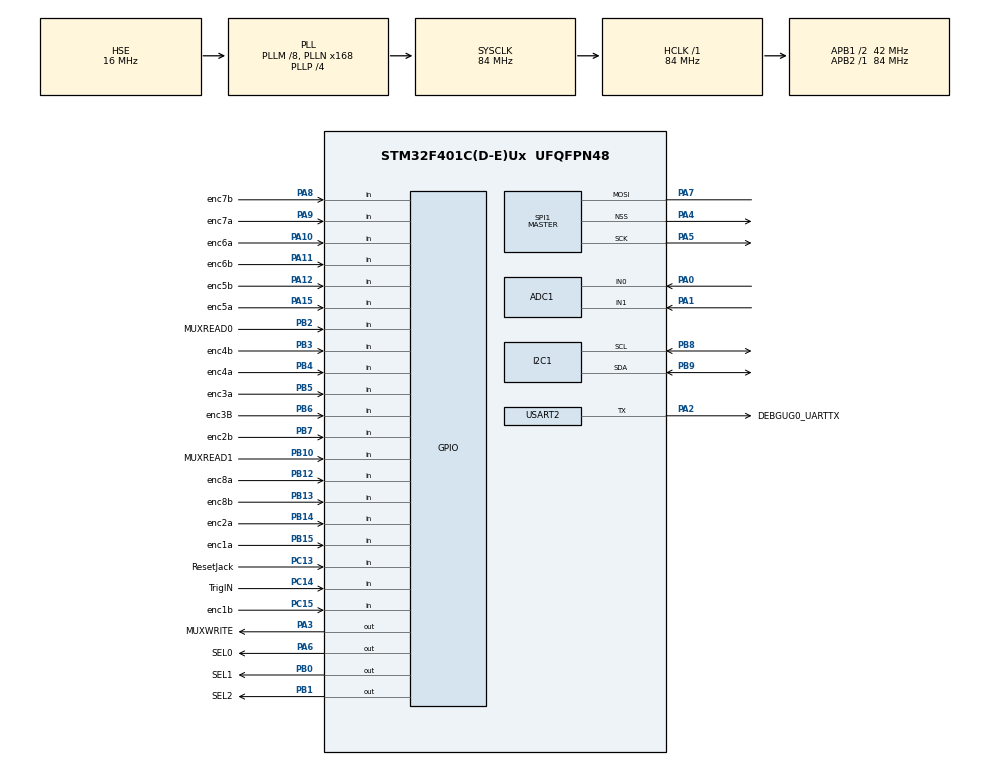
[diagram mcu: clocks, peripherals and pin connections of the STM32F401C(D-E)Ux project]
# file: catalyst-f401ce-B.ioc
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ADC1.Channel-0\#ChannelRegularConversion=ADC_CHANNEL_0
ADC1.Channel-1\#ChannelRegularConversion=ADC_CHANNEL_1
ADC1.ClockPrescaler=ADC_CLOCK_SYNC_PCLK_DIV4
ADC1.ContinuousConvMode=ENABLE
ADC1.DMAContinuousRequests=ENABLE
ADC1.EOCSelection=ADC_EOC_SEQ_CONV
ADC1.NbrOfConversion=2
ADC1.NbrOfConversionFlag=1
ADC1.Rank-0\#ChannelRegularConversion=1
ADC1.Rank-1\#ChannelRegularConversion=2
ADC1.SamplingTime-0\#ChannelRegularConversion=ADC_SAMPLETIME_84CYCLES
ADC1.SamplingTime-1\#ChannelRegularConversion=ADC_SAMPLETIME_84CYCLES
ADC1.ScanConvMode=ENABLE
ADC1.master=1
Dma.ADC1.0.Direction=DMA_PERIPH_TO_MEMORY
Dma.ADC1.0.FIFOMode=DMA_FIFOMODE_DISABLE
Dma.ADC1.0.Instance=DMA2_Stream0
Dma.ADC1.0.MemDataAlignment=DMA_MDATAALIGN_HALFWORD
Dma.ADC1.0.MemInc=DMA_MINC_ENABLE
Dma.ADC1.0.Mode=DMA_NORMAL
Dma.ADC1.0.PeriphDataAlignment=DMA_PDATAALIGN_HALFWORD
Dma.ADC1.0.PeriphInc=DMA_PINC_DISABLE
Dma.ADC1.0.Priority=DMA_PRIORITY_LOW
Dma.Request0=ADC1
I2C1.I2C_Mode=I2C_Fast
Mcu.Family=STM32F4
Mcu.Name=STM32F401C(D-E)Ux
Mcu.Package=UFQFPN48
NVIC.DMA2_Stream0_IRQn=true\:0\:0\:false\:false\:true\:false\:true\:true
NVIC.PriorityGroup=NVIC_PRIORITYGROUP_4
PA0-WKUP.Signal=ADCx_IN0
PA1.Signal=ADCx_IN1
PA10.GPIO_Label=enc6a
PA10.Signal=GPIO_Input
PA11.GPIO_Label=enc6b
PA11.Signal=GPIO_Input
PA12.GPIO_Label=enc5b
PA12.Signal=GPIO_Input
PA13.Mode=Serial_Wire
PA13.Signal=SYS_JTMS-SWDIO
PA14.Mode=Serial_Wire
PA14.Signal=SYS_JTCK-SWCLK
PA15.GPIO_Label=enc5a
PA15.Signal=GPIO_Input
PA2.GPIO_Label=DEBGUG0_UARTTX
PA2.Mode=Half_duplex(single_wire_mode)
PA2.Signal=USART2_TX
PA3.GPIO_Label=MUXWRITE
PA3.Signal=GPIO_Output
PA4.Mode=NSS_Signal_Hard_Output
PA4.Signal=SPI1_NSS
PA5.Mode=Simplex_Bidirectional_Master
PA5.Signal=SPI1_SCK
PA6.GPIO_Label=SEL0
PA6.Signal=GPIO_Output
PA7.Mode=Simplex_Bidirectional_Master
PA7.Signal=SPI1_MOSI
PA8.GPIO_Label=enc7b
PA8.Signal=GPIO_Input
PA9.GPIO_Label=enc7a
PA9.Signal=GPIO_Input
PB0.GPIO_Label=SEL1
PB0.Signal=GPIO_Output
PB1.GPIO_Label=SEL2
PB1.Signal=GPIO_Output
PB10.GPIO_Label=MUXREAD1
PB10.Signal=GPIO_Input
PB12.GPIO_Label=enc8a
PB12.Signal=GPIO_Input
PB13.GPIO_Label=enc8b
PB13.Signal=GPIO_Input
PB14.GPIO_Label=enc2a
PB14.Signal=GPIO_Input
PB15.GPIO_Label=enc1a
PB15.Signal=GPIO_Input
PB2.GPIO_Label=MUXREAD0
PB2.Signal=GPIO_Input
PB3.GPIO_Label=enc4b
PB3.Signal=GPIO_Input
PB4.GPIO_Label=enc4a
PB4.Signal=GPIO_Input
PB5.GPIO_Label=enc3a
PB5.Signal=GPIO_Input
PB6.GPIO_Label=enc3B
PB6.Signal=GPIO_Input
PB7.GPIO_Label=enc2b
PB7.Signal=GPIO_Input
PB8.Mode=I2C
PB8.Signal=I2C1_SCL
PB9.Mode=I2C
PB9.Signal=I2C1_SDA
PC13-ANTI_TAMP.GPIO_Label=ResetJack
PC13-ANTI_TAMP.Signal=GPIO_Input
PC14-OSC32_IN.GPIO_Label=TrigIN
PC14-OSC32_IN.Signal=GPIO_Input
PC15-OSC32_OUT.GPIO_Label=enc1b
PC15-OSC32_OUT.Signal=GPIO_Input
PH0\ -\ OSC_IN.Mode=HSE-External-Oscillator
PH0\ -\ OSC_IN.Signal=RCC_OSC_IN
PH1\ -\ OSC_OUT.Mode=HSE-External-Oscillator
PH1\ -\ OSC_OUT.Signal=RCC_OSC_OUT
ProjectManager.HeapSize=0x200
ProjectManager.StackSize=0x400
ProjectManager.TargetToolchain=Makefile
RCC.48MHZClocksFreq_Value=48000000
RCC.AHBFreq_Value=84000000
RCC.APB1CLKDivider=RCC_HCLK_DIV2
RCC.APB1Freq_Value=42000000
RCC.APB1TimFreq_Value=84000000
RCC.APB2Freq_Value=84000000
RCC.APB2TimFreq_Value=84000000
RCC.CortexFreq_Value=84000000
RCC.HCLKFreq_Value=84000000
RCC.HSE_VALUE=16000000
RCC.HSI_VALUE=16000000
RCC.LSE_VALUE=32768
RCC.PLLM=8
RCC.PLLN=168
RCC.PLLP=RCC_PLLP_DIV4
RCC.PLLQ=7
RCC.PLLSourceVirtual=RCC_PLLSOURCE_HSE
RCC.SYSCLKFreq_VALUE=84000000
RCC.SYSCLKSource=RCC_SYSCLKSOURCE_PLLCLK
RCC.VCOOutputFreq_Value=336000000
SH.ADCx_IN0.0=ADC1_IN0,IN0
SH.ADCx_IN1.0=ADC1_IN1,IN1
SPI1.Direction=SPI_DIRECTION_1LINE
SPI1.Mode=SPI_MODE_MASTER
SPI1.VirtualNSS=VM_NSSHARD
SPI1.VirtualType=VM_MASTER
USART2.Mode=MODE_TX
USART2.VirtualMode=VM_ASYNC
board=custom

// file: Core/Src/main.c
#include "main.h"
#include "stm32f4xx_hal_i2c.h"

ADC_HandleTypeDef hadc1;
DMA_HandleTypeDef hdma_adc1;

I2C_HandleTypeDef hi2c1;

SPI_HandleTypeDef hspi1;

void SystemClock_Config(void);
static void MX_GPIO_Init(void);
static void MX_DMA_Init(void);
static void MX_ADC1_Init(void);
static void MX_SPI1_Init(void);
static void MX_I2C1_Init(void);

//
// LEDs
//

HAL_StatusTypeDef write_leddrv(uint8_t reg, uint8_t data)
{
	HAL_StatusTypeDef err;

	err = HAL_I2C_Mem_Write(&hi2c1, 0b01010000, reg, I2C_MEMADD_SIZE_8BIT, &data, 1, 0xFFFF);
	if (err != HAL_OK)
		HAL_GPIO_WritePin(DEBUG1_GPIO_Port, DEBUG1_Pin, GPIO_PIN_SET);

	return err;
}

void init_leds()
{
	// Use PA2 to indicate an error
	HAL_GPIO_WritePin(DEBUG1_GPIO_Port, DEBUG1_Pin, GPIO_PIN_RESET);

	// enable chip
	write_leddrv(0, (1 << 6));

	// dither + auto inc + no auto power save + log
	write_leddrv(1, 0x2C);

	// no bank mode
	write_leddrv(2, 0);

	// all lights off
	for (uint8_t i = 0; i < 24; i++)
		write_leddrv(0xF + i, 0);
}

void test_leds()
{
	for (uint8_t el = 0; el < 24; el++) {

		// fade on next element
		for (uint8_t intensity = 0; intensity < 0xFF; intensity++) {
			write_leddrv(0xF + el, intensity);
			HAL_Delay(1);
		}

		write_leddrv(0xF + el, 0);
	}
	// fade all lights up
	for (uint8_t intensity = 0; intensity < 0xFF; intensity++) {
		for (uint8_t i = 0; i < 24; i++) {
			write_leddrv(0xF + i, intensity);
		}
		HAL_Delay(1);
	}

	// all lights off
	for (uint8_t i = 0; i < 24; i++)
		write_leddrv(0xF + i, 0);
}

//
// MUX IO
//

void set_mux_select(uint8_t sel)
{
	HAL_GPIO_WritePin(SEL0_GPIO_Port, SEL0_Pin, (sel & 0b001));
	HAL_GPIO_WritePin(SEL1_GPIO_Port, SEL1_Pin, (sel & 0b010));
	HAL_GPIO_WritePin(SEL2_GPIO_Port, SEL2_Pin, (sel & 0b100));
}

void write_to_mux(uint8_t val)
{
	for (unsigned chan = 0; chan < 8; chan++) {
		set_mux_select(chan);
		HAL_GPIO_WritePin(MUXWRITE_GPIO_Port, MUXWRITE_Pin, (val & (1 << chan)));
		HAL_Delay(1);
	}
}

uint16_t read_from_muxes()
{
	uint16_t read = 0;
	for (unsigned chan = 0; chan < 8; chan++) {
		set_mux_select(chan);
		// HAL_Delay(1);

		GPIO_PinState r = HAL_GPIO_ReadPin(MUXREAD0_GPIO_Port, MUXREAD0_Pin);
		if (r == GPIO_PIN_SET)
			read |= (1 << chan);

		r = HAL_GPIO_ReadPin(MUXREAD1_GPIO_Port, MUXREAD1_Pin);
		if (r == GPIO_PIN_SET)
			read |= (1 << chan);

		// HAL_Delay(1);
	}
	return read;
}

uint16_t read_write_to_mux(uint8_t val)
{
	uint16_t read = 0;
	for (unsigned chan = 0; chan < 8; chan++) {
		HAL_GPIO_WritePin(MUXWRITE_GPIO_Port, MUXWRITE_Pin, 0);
		set_mux_select(chan);

		HAL_GPIO_WritePin(MUXWRITE_GPIO_Port, MUXWRITE_Pin, (val & (1 << chan)));

		// HAL_Delay(1);

		if (HAL_GPIO_ReadPin(MUXREAD1_GPIO_Port, MUXREAD1_Pin))
			read |= (1 << chan);

		if (HAL_GPIO_ReadPin(MUXREAD0_GPIO_Port, MUXREAD0_Pin))
			read |= (1 << chan) << 8U;
	}
	return read;
}

void test_tmux_timing()
{
	while (1) {
		GPIO_PinState r = read_write_to_mux(0) > 0 ? GPIO_PIN_SET : GPIO_PIN_RESET;
		HAL_GPIO_WritePin(DEBUG1_GPIO_Port, DEBUG1_Pin, r);
	}
}

void test_tmux_read()
{
	uint16_t buttons1 = 0;
	while (1) {
		buttons1 = read_from_muxes();

		for (uint8_t led = 0; led < 8; led++) {
			uint8_t mux0_button_pressed = buttons1 & (1 << led) ? 100 : 0;
			uint8_t mux1_button_pressed = buttons1 & (1 << (led + 8)) ? 100 : 0;

			write_leddrv(0xF + led * 3, mux0_button_pressed);
			write_leddrv(0xF + led * 3 + 1, mux1_button_pressed);
		}

		HAL_Delay(100);
	}
}

void test_tmux_readwrite()
{
	uint8_t light = 0;
	while (1) {
		uint16_t buttons = read_write_to_mux(light);
		light = buttons & 0xFF;
	}
	// all off
	write_to_mux(0);
}

//
// DAC
//

void write_dac(uint8_t data[3])
{
	HAL_GPIO_WritePin(GPIOA, GPIO_PIN_4, GPIO_PIN_RESET);
	HAL_SPI_Transmit(&hspi1, (uint8_t *)data, 3, 0xFFFF);
	HAL_GPIO_WritePin(GPIOA, GPIO_PIN_4, GPIO_PIN_SET);
}

void test_dac()
{
	uint8_t data[3];
	data[0] = 0b01000000; // all channels power up
	data[1] = 0;
	data[2] = 0;
	write_dac(data);

	uint8_t pressed = 0;
	data[0] = 0b00110000; // Write and update channel 0
	data[1] = 128;
	data[2] = 0x55;
	while (1) {
		write_dac(data);
		data[1] += 1;

		uint16_t r = read_from_muxes() & 0x0001; // Alt button
		if (r) {
			if (!pressed) {
				pressed = 1;
				data[0] = 0b00110000 | ((data[0] + 1) & 7);
			}
		} else
			pressed = 0;
	}
}

//
// ADC
//

static uint16_t adcbuff[2];
void init_adc() { HAL_ADC_Start_DMA(&hadc1, (uint32_t *)&adcbuff, 2); }
void HAL_ADC_ConvCpltCallback(ADC_HandleTypeDef *hadc)
{
	// runs at about 283kHz on p2 with -O3
	//  Noise can be around 40/4096 (5.5bits)
	//  if we oversample by 16 (+4 bits), we get 17kHz sample rate
	//  if we oversample by 64 (+6 bits) we get 4kHz sample rate
	// HAL_GPIO_WritePin(DEBUG1_GPIO_Port, DEBUG1_Pin, GPIO_PIN_SET);
	// HAL_GPIO_WritePin(DEBUG1_GPIO_Port, DEBUG1_Pin, GPIO_PIN_RESET);
}

void test_dac_adc()
{
	uint8_t data[3];
	data[0] = 0b01000000; // all channels power up
	data[1] = 0;
	data[2] = 0;
	write_dac(data);

	uint8_t pressed = 0;
	data[0] = 0b00110000; // Write and update channel 0
	data[1] = 128;
	data[2] = 0x55;
	while (1) {
		write_dac(data);
		// data[1] += 1;
		data[2] = adcbuff[1] & 0xFF;
		data[1] = adcbuff[1] >> 8;

		uint16_t r = read_from_muxes() & 0x0001; // Alt button
		if (r) {
			if (!pressed) {
				pressed = 1;
				data[0] = 0b00110000 | ((data[0] + 1) & 7);
			}
		} else
			pressed = 0;
	}
}

void test_dac_adc_leds()
{
	uint8_t data[3];
	data[0] = 0b01000000; // all channels power up
	data[1] = 0;
	data[2] = 0;
	write_dac(data);

	uint8_t pressed = 0;
	data[0] = 0b00110000; // Write and update channel 0
	data[1] = 128;
	data[2] = 0x55;

	uint8_t intensity = 0;
	uint8_t el = 0;
	while (1) {
		write_dac(data);
		// data[1] += 1;
		data[2] = adcbuff[1] & 0xFF;
		data[1] = adcbuff[1] >> 8;

		uint16_t r = read_from_muxes() & 0b0011; // Alt button or ? button
		if (r == 0b0001) {
			if (!pressed) {
				pressed = 1;
				data[0] = 0b00110000 | ((data[0] + 1) & 7);
			}
		} else
			pressed = 0;

		// fade LEDs randomly

		if (r != 0b0010) {
			write_leddrv(0xF + el, intensity);
			intensity += adcbuff[1] * 0xA7;
			if (++el >= 24)
				el = 0;
		}
	}
}

// Trig inputs
void test_trig_in()
{
	do {
		GPIO_PinState r = HAL_GPIO_ReadPin(TrigIN_GPIO_Port, TrigIN_Pin);
		HAL_GPIO_WritePin(DEBUG1_GPIO_Port, DEBUG1_Pin, r);
	} while ((read_from_muxes() & 0x0001) == 0);
	while ((read_from_muxes() & 0x0001) == 1)
		;
}
void test_reset_in()
{
	do {
		GPIO_PinState r = HAL_GPIO_ReadPin(ResetJack_GPIO_Port, ResetJack_Pin);
		HAL_GPIO_WritePin(DEBUG1_GPIO_Port, DEBUG1_Pin, r);
	} while ((read_from_muxes() & 0x0001) == 0);
	while ((read_from_muxes() & 0x0001) == 1)
		;
}

int main(void)
{
	HAL_Init();
	SystemClock_Config();

	MX_GPIO_Init();
	MX_DMA_Init();
	MX_ADC1_Init();
	MX_SPI1_Init();
	MX_I2C1_Init();
  MX_USART2_UART_Init();
	init_adc(); // on p2: 400kHz
	init_leds();

	GPIO_InitTypeDef GPIO_InitStruct;
	GPIO_InitStruct.Pin = enc8a_Pin | enc8b_Pin;
	GPIO_InitStruct.Mode = GPIO_MODE_INPUT;
	GPIO_InitStruct.Pull = GPIO_PULLUP;
	HAL_GPIO_Init(enc8b_GPIO_Port, &GPIO_InitStruct);

	GPIO_InitStruct.Pin = enc8a_Pin | enc8b_Pin;
	HAL_GPIO_Init(enc8b_GPIO_Port, &GPIO_InitStruct);

	// test_trig_in();

	// test_reset_in();
	test_leds();
	// test_tmux_read();
	test_tmux_readwrite();
	// test_tmux_timing(); // on p2: max 200uS
	// test_dac();
	// test_dac_adc();
	// test_dac_adc_leds();

	while (1) {
	}
}

void SystemClock_Config(void)
{
	RCC_OscInitTypeDef RCC_OscInitStruct = {0};
	RCC_ClkInitTypeDef RCC_ClkInitStruct = {0};

	/** Configure the main internal regulator output voltage
	 */
	__HAL_RCC_PWR_CLK_ENABLE();
	__HAL_PWR_VOLTAGESCALING_CONFIG(PWR_REGULATOR_VOLTAGE_SCALE2);

	/** Initializes the RCC Oscillators according to the specified parameters
	 * in the RCC_OscInitTypeDef structure.
	 */
	RCC_OscInitStruct.OscillatorType = RCC_OSCILLATORTYPE_HSE;
	RCC_OscInitStruct.HSEState = RCC_HSE_ON;
	RCC_OscInitStruct.PLL.PLLState = RCC_PLL_ON;
	RCC_OscInitStruct.PLL.PLLSource = RCC_PLLSOURCE_HSE;
	RCC_OscInitStruct.PLL.PLLM = 8;
	RCC_OscInitStruct.PLL.PLLN = 168;
	RCC_OscInitStruct.PLL.PLLP = RCC_PLLP_DIV4;
	RCC_OscInitStruct.PLL.PLLQ = 7;
	if (HAL_RCC_OscConfig(&RCC_OscInitStruct) != HAL_OK) {
		Error_Handler();
	}

	/** Initializes the CPU, AHB and APB buses clocks
	 */
	RCC_ClkInitStruct.ClockType = RCC_CLOCKTYPE_HCLK | RCC_CLOCKTYPE_SYSCLK | RCC_CLOCKTYPE_PCLK1 | RCC_CLOCKTYPE_PCLK2;
	RCC_ClkInitStruct.SYSCLKSource = RCC_SYSCLKSOURCE_PLLCLK;
	RCC_ClkInitStruct.AHBCLKDivider = RCC_SYSCLK_DIV1;
	RCC_ClkInitStruct.APB1CLKDivider = RCC_HCLK_DIV2;
	RCC_ClkInitStruct.APB2CLKDivider = RCC_HCLK_DIV1;

	if (HAL_RCC_ClockConfig(&RCC_ClkInitStruct, FLASH_LATENCY_2) != HAL_OK) {
		Error_Handler();
	}
}

static void MX_ADC1_Init(void)
{

	ADC_ChannelConfTypeDef sConfig = {0};

	/** Configure the global features of the ADC (Clock, Resolution, Data
	 * Alignment and number of conversion)
	 */
	hadc1.Instance = ADC1;
	hadc1.Init.ClockPrescaler = ADC_CLOCK_SYNC_PCLK_DIV2;
	hadc1.Init.Resolution = ADC_RESOLUTION_12B;
	hadc1.Init.ScanConvMode = ENABLE;
	hadc1.Init.ContinuousConvMode = ENABLE;
	hadc1.Init.DiscontinuousConvMode = DISABLE;
	hadc1.Init.ExternalTrigConvEdge = ADC_EXTERNALTRIGCONVEDGE_NONE;
	hadc1.Init.ExternalTrigConv = ADC_SOFTWARE_START;
	hadc1.Init.DataAlign = ADC_DATAALIGN_LEFT;
	hadc1.Init.NbrOfConversion = 2;
	hadc1.Init.DMAContinuousRequests = ENABLE;
	hadc1.Init.EOCSelection = ADC_EOC_SINGLE_SEQ_CONV;
	if (HAL_ADC_Init(&hadc1) != HAL_OK) {
		Error_Handler();
	}

	/** Configure for the selected ADC regular channel its corresponding rank in
	 * the sequencer and its sample time.
	 */
	sConfig.Channel = ADC_CHANNEL_0;
	sConfig.Rank = 1;
	sConfig.SamplingTime = ADC_SAMPLETIME_56CYCLES;
	if (HAL_ADC_ConfigChannel(&hadc1, &sConfig) != HAL_OK) {
		Error_Handler();
	}

	sConfig.Channel = ADC_CHANNEL_1;
	sConfig.Rank = 2;
	sConfig.SamplingTime = ADC_SAMPLETIME_56CYCLES;
	if (HAL_ADC_ConfigChannel(&hadc1, &sConfig) != HAL_OK) {
		Error_Handler();
	}
}

static void MX_I2C1_Init(void)
{

  hi2c1.Instance = I2C1;
  hi2c1.Init.ClockSpeed = 400000;
  hi2c1.Init.DutyCycle = I2C_DUTYCYCLE_2;
  hi2c1.Init.OwnAddress1 = 0;
  hi2c1.Init.AddressingMode = I2C_ADDRESSINGMODE_7BIT;
	hi2c1.Init.DualAddressMode = I2C_DUALADDRESS_DISABLE;
	hi2c1.Init.OwnAddress2 = 0;
	hi2c1.Init.GeneralCallMode = I2C_GENERALCALL_DISABLE;
	hi2c1.Init.NoStretchMode = I2C_NOSTRETCH_DISABLE;
	if (HAL_I2C_Init(&hi2c1) != HAL_OK) {
		Error_Handler();
	}
}

static void MX_SPI1_Init(void)
{

	/* USER CODE BEGIN SPI1_Init 0 */
	// GPIO_InitTypeDef GPIO_InitStruct;
	// GPIO_InitStruct.Pin = GPIO_PIN_4;
	// GPIO_InitStruct.Mode = GPIO_MODE_OUTPUT_PP;
	// GPIO_InitStruct.Pull = GPIO_NOPULL;
	// GPIO_InitStruct.Speed = GPIO_SPEED_FREQ_VERY_HIGH;
	// HAL_GPIO_Init(GPIOA, &GPIO_InitStruct);
	// for (int i = 0; i < 100000; i++) {
	// 	HAL_GPIO_WritePin(GPIOA, GPIO_PIN_4, 1);
	// 	HAL_GPIO_WritePin(GPIOA, GPIO_PIN_4, 0);
	// }

	/* USER CODE END SPI1_Init 0 */

	/* SPI1 parameter configuration*/
	hspi1.Instance = SPI1;
	hspi1.Init.Mode = SPI_MODE_MASTER;
	hspi1.Init.Direction = SPI_DIRECTION_1LINE;
	hspi1.Init.DataSize = SPI_DATASIZE_8BIT;
	hspi1.Init.CLKPolarity = SPI_POLARITY_LOW;
	hspi1.Init.CLKPhase = SPI_PHASE_1EDGE;
	hspi1.Init.NSS = SPI_NSS_SOFT;
	hspi1.Init.BaudRatePrescaler = SPI_BAUDRATEPRESCALER_16;
	hspi1.Init.FirstBit = SPI_FIRSTBIT_MSB;
	hspi1.Init.TIMode = SPI_TIMODE_DISABLE;
	hspi1.Init.CRCCalculation = SPI_CRCCALCULATION_DISABLE;
	hspi1.Init.CRCPolynomial = 10;
	if (HAL_SPI_Init(&hspi1) != HAL_OK) {
		Error_Handler();
	}
}

static void MX_USART2_UART_Init(void)
{

  huart2.Instance = USART2;
  huart2.Init.BaudRate = 115200;
  huart2.Init.WordLength = UART_WORDLENGTH_8B;
  huart2.Init.StopBits = UART_STOPBITS_1;
  huart2.Init.Parity = UART_PARITY_NONE;
  huart2.Init.Mode = UART_MODE_TX_RX;
  huart2.Init.HwFlowCtl = UART_HWCONTROL_NONE;
  huart2.Init.OverSampling = UART_OVERSAMPLING_16;
  if (HAL_HalfDuplex_Init(&huart2) != HAL_OK)
  {
    Error_Handler();
  }

}

static void MX_DMA_Init(void)
{

	/* DMA controller clock enable */
	__HAL_RCC_DMA2_CLK_ENABLE();

	/* DMA interrupt init */
	/* DMA2_Stream0_IRQn interrupt configuration */
	// HAL_NVIC_SetPriority(DMA2_Stream0_IRQn, 0, 0);
	// HAL_NVIC_EnableIRQ(DMA2_Stream0_IRQn);
}

static void MX_GPIO_Init(void)
{
	GPIO_InitTypeDef GPIO_InitStruct = {0};

	/* GPIO Ports Clock Enable */
	__HAL_RCC_GPIOC_CLK_ENABLE();
	__HAL_RCC_GPIOH_CLK_ENABLE();
	__HAL_RCC_GPIOA_CLK_ENABLE();
	__HAL_RCC_GPIOB_CLK_ENABLE();

	/*Configure GPIO pin Output Level */
	HAL_GPIO_WritePin(GPIOA, DEBUG1_Pin | MUXWRITE_Pin | SEL0_Pin, GPIO_PIN_RESET);

	/*Configure GPIO pin Output Level */
	HAL_GPIO_WritePin(GPIOB, SEL1_Pin | SEL2_Pin, GPIO_PIN_RESET);

	/*Configure GPIO pins : ResetJack_Pin TrigIN_Pin enc1b_Pin */
	GPIO_InitStruct.Pin = ResetJack_Pin | TrigIN_Pin | enc1b_Pin;
	GPIO_InitStruct.Mode = GPIO_MODE_INPUT;
	GPIO_InitStruct.Pull = GPIO_NOPULL;
	HAL_GPIO_Init(GPIOC, &GPIO_InitStruct);

	/*Configure GPIO pins : DEBUG1_Pin MUXWRITE_Pin SEL0_Pin */
	GPIO_InitStruct.Pin = DEBUG1_Pin | MUXWRITE_Pin | SEL0_Pin;
	GPIO_InitStruct.Mode = GPIO_MODE_OUTPUT_PP;
	GPIO_InitStruct.Pull = GPIO_NOPULL;
	GPIO_InitStruct.Speed = GPIO_SPEED_FREQ_LOW;
	HAL_GPIO_Init(GPIOA, &GPIO_InitStruct);

	/*Configure GPIO pins : SEL1_Pin SEL2_Pin */
	GPIO_InitStruct.Pin = SEL1_Pin | SEL2_Pin;
	GPIO_InitStruct.Mode = GPIO_MODE_OUTPUT_PP;
	GPIO_InitStruct.Pull = GPIO_NOPULL;
	GPIO_InitStruct.Speed = GPIO_SPEED_FREQ_LOW;
	HAL_GPIO_Init(GPIOB, &GPIO_InitStruct);

	/*Configure GPIO pins : MUXREAD0_Pin MUXREAD1_Pin enc8a_Pin enc8b_Pin
							 enc2a_Pin enc1a_Pin enc4b_Pin enc4a_Pin
							 enc3a_Pin enc3B_Pin enc2b_Pin */
	GPIO_InitStruct.Pin = MUXREAD0_Pin | MUXREAD1_Pin | enc8a_Pin | enc8b_Pin | enc2a_Pin | enc1a_Pin | enc4b_Pin |
						  enc4a_Pin | enc3a_Pin | enc3B_Pin | enc2b_Pin;
	GPIO_InitStruct.Mode = GPIO_MODE_INPUT;
	GPIO_InitStruct.Pull = GPIO_NOPULL;
	HAL_GPIO_Init(GPIOB, &GPIO_InitStruct);

	/*Configure GPIO pins : enc7b_Pin enc7a_Pin enc6a_Pin enc6b_Pin
							 enc5b_Pin enc5a_Pin */
	GPIO_InitStruct.Pin = enc7b_Pin | enc7a_Pin | enc6a_Pin | enc6b_Pin | enc5b_Pin | enc5a_Pin;
	GPIO_InitStruct.Mode = GPIO_MODE_INPUT;
	GPIO_InitStruct.Pull = GPIO_NOPULL;
	HAL_GPIO_Init(GPIOA, &GPIO_InitStruct);
}

void Error_Handler(void)
{
	/* USER CODE BEGIN Error_Handler_Debug */
	/* User can add his own implementation to report the HAL error return state
	 */
	__disable_irq();
	while (1) {
	}
	/* USER CODE END Error_Handler_Debug */
}

#ifdef USE_FULL_ASSERT
/**
 * @brief  Reports the name of the source file and the source line number
 *         where the assert_param error has occurred.
 * @param  file: pointer to the source file name
 * @param  line: assert_param error line source number
 * @retval None
 */
void assert_failed(uint8_t *file, uint32_t line)
{
	/* USER CODE BEGIN 6 */
	/* User can add his own implementation to report the file name and line
	   number, eg: printf("Wrong parameters value: file %s on line %d\r\n",
	   file, line) */
	/* USER CODE END 6 */
}
#endif /* USE_FULL_ASSERT */
